AUTOSAR XML (schema 00048)
package /AUTOLIV/SoftwareComponents/BFS
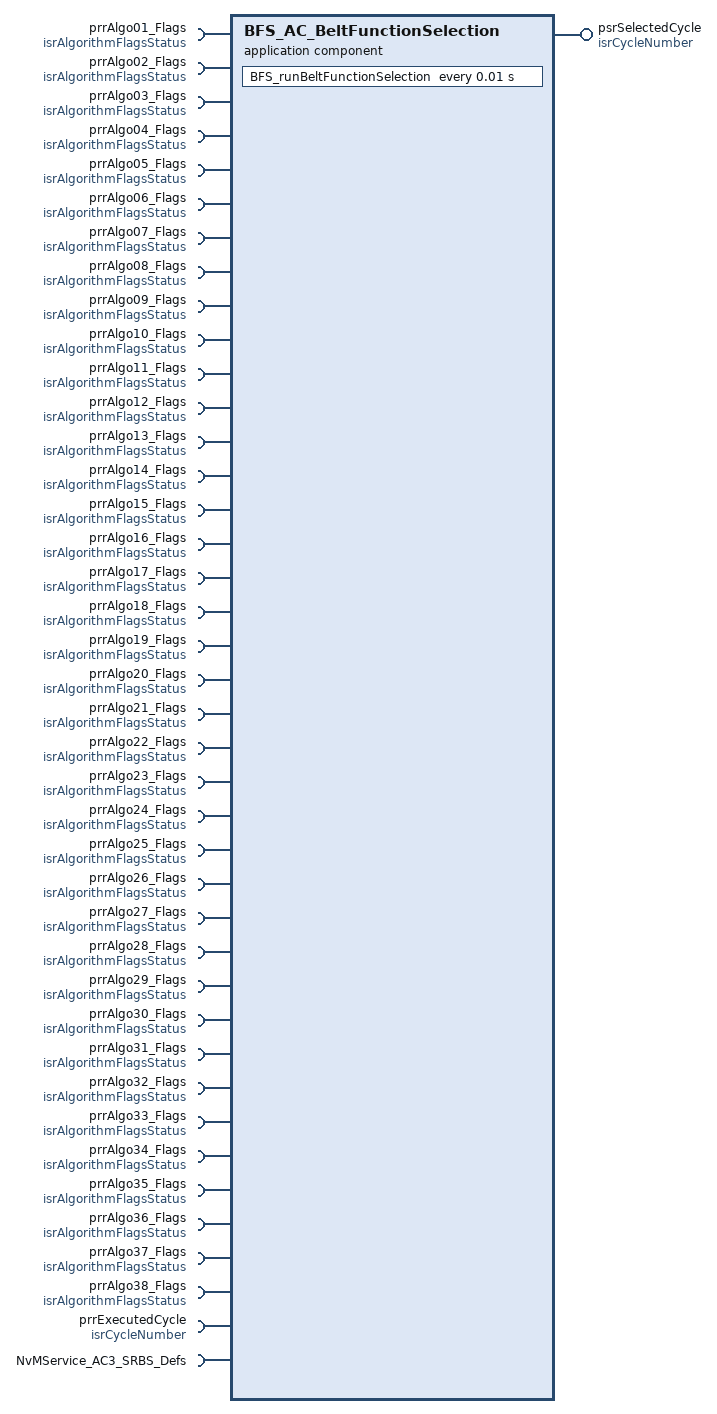
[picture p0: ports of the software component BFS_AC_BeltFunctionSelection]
  application sw component type BFS_AC_BeltFunctionSelection
    39 x require port:
      prrAlgo01_Flags: required-interface=isrAlgorithmFlagsStatus
        required-com-specs:
          data-element=b8InterruptFlag, init-value=constant-reference=APPLINIT_KB8_ALGO_FLAG_FALSE
          data-element=b8PreActivationFlag, init-value=constant-reference=APPLINIT_KB8_ALGO_FLAG_FALSE
          data-element=b8PreConditionsFlag, init-value=constant-reference=APPLINIT_KB8_ALGO_FLAG_FALSE
          data-element=b8TriggerFlag, init-value=constant-reference=APPLINIT_KB8_ALGO_FLAG_FALSE
          data-element=u8TriggeringSource, init-value=constant-reference=APPLINIT_KU8_TRIGGERING_SOURCE_NO
      prrAlgo02_Flags: required-interface=isrAlgorithmFlagsStatus
        required-com-specs:
          data-element=b8InterruptFlag, init-value=constant-reference=APPLINIT_KB8_ALGO_FLAG_FALSE
          data-element=b8PreActivationFlag, init-value=constant-reference=APPLINIT_KB8_ALGO_FLAG_FALSE
          data-element=b8PreConditionsFlag, init-value=constant-reference=APPLINIT_KB8_ALGO_FLAG_FALSE
          data-element=b8TriggerFlag, init-value=constant-reference=APPLINIT_KB8_ALGO_FLAG_FALSE
          data-element=u8TriggeringSource, init-value=constant-reference=APPLINIT_KU8_TRIGGERING_SOURCE_NO
      prrAlgo03_Flags: required-interface=isrAlgorithmFlagsStatus
        required-com-specs:
          data-element=b8InterruptFlag, init-value=constant-reference=APPLINIT_KB8_ALGO_FLAG_FALSE
          data-element=b8PreActivationFlag, init-value=constant-reference=APPLINIT_KB8_ALGO_FLAG_FALSE
          data-element=b8PreConditionsFlag, init-value=constant-reference=APPLINIT_KB8_ALGO_FLAG_FALSE
          data-element=b8TriggerFlag, init-value=constant-reference=APPLINIT_KB8_ALGO_FLAG_FALSE
          data-element=u8TriggeringSource, init-value=constant-reference=APPLINIT_KU8_TRIGGERING_SOURCE_NO
      prrAlgo04_Flags: required-interface=isrAlgorithmFlagsStatus
        required-com-specs:
          data-element=b8InterruptFlag, init-value=constant-reference=APPLINIT_KB8_ALGO_FLAG_FALSE
          data-element=b8PreActivationFlag, init-value=constant-reference=APPLINIT_KB8_ALGO_FLAG_FALSE
          data-element=b8PreConditionsFlag, init-value=constant-reference=APPLINIT_KB8_ALGO_FLAG_FALSE
          data-element=b8TriggerFlag, init-value=constant-reference=APPLINIT_KB8_ALGO_FLAG_FALSE
          data-element=u8TriggeringSource, init-value=constant-reference=APPLINIT_KU8_TRIGGERING_SOURCE_NO
      prrAlgo05_Flags: required-interface=isrAlgorithmFlagsStatus
        required-com-specs:
          data-element=b8InterruptFlag, init-value=constant-reference=APPLINIT_KB8_ALGO_FLAG_FALSE
          data-element=b8PreActivationFlag, init-value=constant-reference=APPLINIT_KB8_ALGO_FLAG_FALSE
          data-element=b8PreConditionsFlag, init-value=constant-reference=APPLINIT_KB8_ALGO_FLAG_FALSE
          data-element=b8TriggerFlag, init-value=constant-reference=APPLINIT_KB8_ALGO_FLAG_FALSE
          data-element=u8TriggeringSource, init-value=constant-reference=APPLINIT_KU8_TRIGGERING_SOURCE_NO
      prrAlgo06_Flags: required-interface=isrAlgorithmFlagsStatus
        required-com-specs:
          data-element=b8InterruptFlag, init-value=constant-reference=APPLINIT_KB8_ALGO_FLAG_FALSE
          data-element=b8PreActivationFlag, init-value=constant-reference=APPLINIT_KB8_ALGO_FLAG_FALSE
          data-element=b8PreConditionsFlag, init-value=constant-reference=APPLINIT_KB8_ALGO_FLAG_FALSE
          data-element=b8TriggerFlag, init-value=constant-reference=APPLINIT_KB8_ALGO_FLAG_FALSE
          data-element=u8TriggeringSource, init-value=constant-reference=APPLINIT_KU8_TRIGGERING_SOURCE_NO
      prrAlgo07_Flags: required-interface=isrAlgorithmFlagsStatus
        required-com-specs:
          data-element=b8InterruptFlag, init-value=constant-reference=APPLINIT_KB8_ALGO_FLAG_FALSE
          data-element=b8PreActivationFlag, init-value=constant-reference=APPLINIT_KB8_ALGO_FLAG_FALSE
          data-element=b8PreConditionsFlag, init-value=constant-reference=APPLINIT_KB8_ALGO_FLAG_FALSE
          data-element=b8TriggerFlag, init-value=constant-reference=APPLINIT_KB8_ALGO_FLAG_FALSE
          data-element=u8TriggeringSource, init-value=constant-reference=APPLINIT_KU8_TRIGGERING_SOURCE_NO
      prrAlgo08_Flags: required-interface=isrAlgorithmFlagsStatus
        required-com-specs:
          data-element=b8InterruptFlag, init-value=constant-reference=APPLINIT_KB8_ALGO_FLAG_FALSE
          data-element=b8PreActivationFlag, init-value=constant-reference=APPLINIT_KB8_ALGO_FLAG_FALSE
          data-element=b8PreConditionsFlag, init-value=constant-reference=APPLINIT_KB8_ALGO_FLAG_FALSE
          data-element=b8TriggerFlag, init-value=constant-reference=APPLINIT_KB8_ALGO_FLAG_FALSE
          data-element=u8TriggeringSource, init-value=constant-reference=APPLINIT_KU8_TRIGGERING_SOURCE_NO
      prrAlgo09_Flags: required-interface=isrAlgorithmFlagsStatus
        required-com-specs:
          data-element=b8InterruptFlag, init-value=constant-reference=APPLINIT_KB8_ALGO_FLAG_FALSE
          data-element=b8PreActivationFlag, init-value=constant-reference=APPLINIT_KB8_ALGO_FLAG_FALSE
          data-element=b8PreConditionsFlag, init-value=constant-reference=APPLINIT_KB8_ALGO_FLAG_FALSE
          data-element=b8TriggerFlag, init-value=constant-reference=APPLINIT_KB8_ALGO_FLAG_FALSE
          data-element=u8TriggeringSource, init-value=constant-reference=APPLINIT_KU8_TRIGGERING_SOURCE_NO
      prrAlgo10_Flags: required-interface=isrAlgorithmFlagsStatus
        required-com-specs:
          data-element=b8InterruptFlag, init-value=constant-reference=APPLINIT_KB8_ALGO_FLAG_FALSE
          data-element=b8PreActivationFlag, init-value=constant-reference=APPLINIT_KB8_ALGO_FLAG_FALSE
          data-element=b8PreConditionsFlag, init-value=constant-reference=APPLINIT_KB8_ALGO_FLAG_FALSE
          data-element=b8TriggerFlag, init-value=constant-reference=APPLINIT_KB8_ALGO_FLAG_FALSE
          data-element=u8TriggeringSource, init-value=constant-reference=APPLINIT_KU8_TRIGGERING_SOURCE_NO
      prrAlgo11_Flags: required-interface=isrAlgorithmFlagsStatus
        required-com-specs:
          data-element=b8InterruptFlag, init-value=constant-reference=APPLINIT_KB8_ALGO_FLAG_FALSE
          data-element=b8PreActivationFlag, init-value=constant-reference=APPLINIT_KB8_ALGO_FLAG_FALSE
          data-element=b8PreConditionsFlag, init-value=constant-reference=APPLINIT_KB8_ALGO_FLAG_FALSE
          data-element=b8TriggerFlag, init-value=constant-reference=APPLINIT_KB8_ALGO_FLAG_FALSE
          data-element=u8TriggeringSource, init-value=constant-reference=APPLINIT_KU8_TRIGGERING_SOURCE_NO
      prrAlgo12_Flags: required-interface=isrAlgorithmFlagsStatus
        required-com-specs:
          data-element=b8InterruptFlag, init-value=constant-reference=APPLINIT_KB8_ALGO_FLAG_FALSE
          data-element=b8PreActivationFlag, init-value=constant-reference=APPLINIT_KB8_ALGO_FLAG_FALSE
          data-element=b8PreConditionsFlag, init-value=constant-reference=APPLINIT_KB8_ALGO_FLAG_FALSE
          data-element=b8TriggerFlag, init-value=constant-reference=APPLINIT_KB8_ALGO_FLAG_FALSE
          data-element=u8TriggeringSource, init-value=constant-reference=APPLINIT_KU8_TRIGGERING_SOURCE_NO
      prrAlgo13_Flags: required-interface=isrAlgorithmFlagsStatus
        required-com-specs:
          data-element=b8InterruptFlag, init-value=constant-reference=APPLINIT_KB8_ALGO_FLAG_FALSE
          data-element=b8PreActivationFlag, init-value=constant-reference=APPLINIT_KB8_ALGO_FLAG_FALSE
          data-element=b8PreConditionsFlag, init-value=constant-reference=APPLINIT_KB8_ALGO_FLAG_FALSE
          data-element=b8TriggerFlag, init-value=constant-reference=APPLINIT_KB8_ALGO_FLAG_FALSE
          data-element=u8TriggeringSource, init-value=constant-reference=APPLINIT_KU8_TRIGGERING_SOURCE_NO
      prrAlgo14_Flags: required-interface=isrAlgorithmFlagsStatus
        required-com-specs:
          data-element=b8InterruptFlag, init-value=constant-reference=APPLINIT_KB8_ALGO_FLAG_FALSE
          data-element=b8PreActivationFlag, init-value=constant-reference=APPLINIT_KB8_ALGO_FLAG_FALSE
          data-element=b8PreConditionsFlag, init-value=constant-reference=APPLINIT_KB8_ALGO_FLAG_FALSE
          data-element=b8TriggerFlag, init-value=constant-reference=APPLINIT_KB8_ALGO_FLAG_FALSE
          data-element=u8TriggeringSource, init-value=constant-reference=APPLINIT_KU8_TRIGGERING_SOURCE_NO
      prrAlgo15_Flags: required-interface=isrAlgorithmFlagsStatus
        required-com-specs:
          data-element=b8InterruptFlag, init-value=constant-reference=APPLINIT_KB8_ALGO_FLAG_FALSE
          data-element=b8PreActivationFlag, init-value=constant-reference=APPLINIT_KB8_ALGO_FLAG_FALSE
          data-element=b8PreConditionsFlag, init-value=constant-reference=APPLINIT_KB8_ALGO_FLAG_FALSE
          data-element=b8TriggerFlag, init-value=constant-reference=APPLINIT_KB8_ALGO_FLAG_FALSE
          data-element=u8TriggeringSource, init-value=constant-reference=APPLINIT_KU8_TRIGGERING_SOURCE_NO
      prrAlgo16_Flags: required-interface=isrAlgorithmFlagsStatus
        required-com-specs:
          data-element=b8InterruptFlag, init-value=constant-reference=APPLINIT_KB8_ALGO_FLAG_FALSE
          data-element=b8PreActivationFlag, init-value=constant-reference=APPLINIT_KB8_ALGO_FLAG_FALSE
          data-element=b8PreConditionsFlag, init-value=constant-reference=APPLINIT_KB8_ALGO_FLAG_FALSE
          data-element=b8TriggerFlag, init-value=constant-reference=APPLINIT_KB8_ALGO_FLAG_FALSE
          data-element=u8TriggeringSource, init-value=constant-reference=APPLINIT_KU8_TRIGGERING_SOURCE_NO
      prrAlgo17_Flags: required-interface=isrAlgorithmFlagsStatus
        required-com-specs:
          data-element=b8InterruptFlag, init-value=constant-reference=APPLINIT_KB8_ALGO_FLAG_FALSE
          data-element=b8PreActivationFlag, init-value=constant-reference=APPLINIT_KB8_ALGO_FLAG_FALSE
          data-element=b8PreConditionsFlag, init-value=constant-reference=APPLINIT_KB8_ALGO_FLAG_FALSE
          data-element=b8TriggerFlag, init-value=constant-reference=APPLINIT_KB8_ALGO_FLAG_FALSE
          data-element=u8TriggeringSource, init-value=constant-reference=APPLINIT_KU8_TRIGGERING_SOURCE_NO
      prrAlgo18_Flags: required-interface=isrAlgorithmFlagsStatus
        required-com-specs:
          data-element=b8InterruptFlag, init-value=constant-reference=APPLINIT_KB8_ALGO_FLAG_FALSE
          data-element=b8PreActivationFlag, init-value=constant-reference=APPLINIT_KB8_ALGO_FLAG_FALSE
          data-element=b8PreConditionsFlag, init-value=constant-reference=APPLINIT_KB8_ALGO_FLAG_FALSE
          data-element=b8TriggerFlag, init-value=constant-reference=APPLINIT_KB8_ALGO_FLAG_FALSE
          data-element=u8TriggeringSource, init-value=constant-reference=APPLINIT_KU8_TRIGGERING_SOURCE_NO
      prrAlgo19_Flags: required-interface=isrAlgorithmFlagsStatus
        required-com-specs:
          data-element=b8InterruptFlag, init-value=constant-reference=APPLINIT_KB8_ALGO_FLAG_FALSE
          data-element=b8PreActivationFlag, init-value=constant-reference=APPLINIT_KB8_ALGO_FLAG_FALSE
          data-element=b8PreConditionsFlag, init-value=constant-reference=APPLINIT_KB8_ALGO_FLAG_FALSE
          data-element=b8TriggerFlag, init-value=constant-reference=APPLINIT_KB8_ALGO_FLAG_FALSE
          data-element=u8TriggeringSource, init-value=constant-reference=APPLINIT_KU8_TRIGGERING_SOURCE_NO
      prrAlgo20_Flags: required-interface=isrAlgorithmFlagsStatus
        required-com-specs:
          data-element=b8InterruptFlag, init-value=constant-reference=APPLINIT_KB8_ALGO_FLAG_FALSE
          data-element=b8PreActivationFlag, init-value=constant-reference=APPLINIT_KB8_ALGO_FLAG_FALSE
          data-element=b8PreConditionsFlag, init-value=constant-reference=APPLINIT_KB8_ALGO_FLAG_FALSE
          data-element=b8TriggerFlag, init-value=constant-reference=APPLINIT_KB8_ALGO_FLAG_FALSE
          data-element=u8TriggeringSource, init-value=constant-reference=APPLINIT_KU8_TRIGGERING_SOURCE_NO
      prrAlgo21_Flags: required-interface=isrAlgorithmFlagsStatus
        required-com-specs:
          data-element=b8InterruptFlag, init-value=constant-reference=APPLINIT_KB8_ALGO_FLAG_FALSE
          data-element=b8PreActivationFlag, init-value=constant-reference=APPLINIT_KB8_ALGO_FLAG_FALSE
          data-element=b8PreConditionsFlag, init-value=constant-reference=APPLINIT_KB8_ALGO_FLAG_FALSE
          data-element=b8TriggerFlag, init-value=constant-reference=APPLINIT_KB8_ALGO_FLAG_FALSE
          data-element=u8TriggeringSource, init-value=constant-reference=APPLINIT_KU8_TRIGGERING_SOURCE_NO
      prrAlgo22_Flags: required-interface=isrAlgorithmFlagsStatus
        required-com-specs:
          data-element=b8InterruptFlag, init-value=constant-reference=APPLINIT_KB8_ALGO_FLAG_FALSE
          data-element=b8PreActivationFlag, init-value=constant-reference=APPLINIT_KB8_ALGO_FLAG_FALSE
          data-element=b8PreConditionsFlag, init-value=constant-reference=APPLINIT_KB8_ALGO_FLAG_FALSE
          data-element=b8TriggerFlag, init-value=constant-reference=APPLINIT_KB8_ALGO_FLAG_FALSE
          data-element=u8TriggeringSource, init-value=constant-reference=APPLINIT_KU8_TRIGGERING_SOURCE_NO
      prrAlgo23_Flags: required-interface=isrAlgorithmFlagsStatus
        required-com-specs:
          data-element=b8InterruptFlag, init-value=constant-reference=APPLINIT_KB8_ALGO_FLAG_FALSE
          data-element=b8PreActivationFlag, init-value=constant-reference=APPLINIT_KB8_ALGO_FLAG_FALSE
          data-element=b8PreConditionsFlag, init-value=constant-reference=APPLINIT_KB8_ALGO_FLAG_FALSE
          data-element=b8TriggerFlag, init-value=constant-reference=APPLINIT_KB8_ALGO_FLAG_FALSE
          data-element=u8TriggeringSource, init-value=constant-reference=APPLINIT_KU8_TRIGGERING_SOURCE_NO
      prrAlgo24_Flags: required-interface=isrAlgorithmFlagsStatus
        required-com-specs:
          data-element=b8InterruptFlag, init-value=constant-reference=APPLINIT_KB8_ALGO_FLAG_FALSE
          data-element=b8PreActivationFlag, init-value=constant-reference=APPLINIT_KB8_ALGO_FLAG_FALSE
          data-element=b8PreConditionsFlag, init-value=constant-reference=APPLINIT_KB8_ALGO_FLAG_FALSE
          data-element=b8TriggerFlag, init-value=constant-reference=APPLINIT_KB8_ALGO_FLAG_FALSE
          data-element=u8TriggeringSource, init-value=constant-reference=APPLINIT_KU8_TRIGGERING_SOURCE_NO
      prrAlgo25_Flags: required-interface=isrAlgorithmFlagsStatus
        required-com-specs:
          data-element=b8InterruptFlag, init-value=constant-reference=APPLINIT_KB8_ALGO_FLAG_FALSE
          data-element=b8PreActivationFlag, init-value=constant-reference=APPLINIT_KB8_ALGO_FLAG_FALSE
          data-element=b8PreConditionsFlag, init-value=constant-reference=APPLINIT_KB8_ALGO_FLAG_FALSE
          data-element=b8TriggerFlag, init-value=constant-reference=APPLINIT_KB8_ALGO_FLAG_FALSE
          data-element=u8TriggeringSource, init-value=constant-reference=APPLINIT_KU8_TRIGGERING_SOURCE_NO
      prrAlgo26_Flags: required-interface=isrAlgorithmFlagsStatus
        required-com-specs:
          data-element=b8InterruptFlag, init-value=constant-reference=APPLINIT_KB8_ALGO_FLAG_FALSE
          data-element=b8PreActivationFlag, init-value=constant-reference=APPLINIT_KB8_ALGO_FLAG_FALSE
          data-element=b8PreConditionsFlag, init-value=constant-reference=APPLINIT_KB8_ALGO_FLAG_FALSE
          data-element=b8TriggerFlag, init-value=constant-reference=APPLINIT_KB8_ALGO_FLAG_FALSE
          data-element=u8TriggeringSource, init-value=constant-reference=APPLINIT_KU8_TRIGGERING_SOURCE_NO
      prrAlgo27_Flags: required-interface=isrAlgorithmFlagsStatus
        required-com-specs:
          data-element=b8InterruptFlag, init-value=constant-reference=APPLINIT_KB8_ALGO_FLAG_FALSE
          data-element=b8PreActivationFlag, init-value=constant-reference=APPLINIT_KB8_ALGO_FLAG_FALSE
          data-element=b8PreConditionsFlag, init-value=constant-reference=APPLINIT_KB8_ALGO_FLAG_FALSE
          data-element=b8TriggerFlag, init-value=constant-reference=APPLINIT_KB8_ALGO_FLAG_FALSE
          data-element=u8TriggeringSource, init-value=constant-reference=APPLINIT_KU8_TRIGGERING_SOURCE_NO
      prrAlgo28_Flags: required-interface=isrAlgorithmFlagsStatus
        required-com-specs:
          data-element=b8InterruptFlag, init-value=constant-reference=APPLINIT_KB8_ALGO_FLAG_FALSE
          data-element=b8PreActivationFlag, init-value=constant-reference=APPLINIT_KB8_ALGO_FLAG_FALSE
          data-element=b8PreConditionsFlag, init-value=constant-reference=APPLINIT_KB8_ALGO_FLAG_FALSE
          data-element=b8TriggerFlag, init-value=constant-reference=APPLINIT_KB8_ALGO_FLAG_FALSE
          data-element=u8TriggeringSource, init-value=constant-reference=APPLINIT_KU8_TRIGGERING_SOURCE_NO
      prrAlgo29_Flags: required-interface=isrAlgorithmFlagsStatus
        required-com-specs:
          data-element=b8InterruptFlag, init-value=constant-reference=APPLINIT_KB8_ALGO_FLAG_FALSE
          data-element=b8PreActivationFlag, init-value=constant-reference=APPLINIT_KB8_ALGO_FLAG_FALSE
          data-element=b8PreConditionsFlag, init-value=constant-reference=APPLINIT_KB8_ALGO_FLAG_FALSE
          data-element=b8TriggerFlag, init-value=constant-reference=APPLINIT_KB8_ALGO_FLAG_FALSE
          data-element=u8TriggeringSource, init-value=constant-reference=APPLINIT_KU8_TRIGGERING_SOURCE_NO
      prrAlgo30_Flags: required-interface=isrAlgorithmFlagsStatus
        required-com-specs:
          data-element=b8InterruptFlag, init-value=constant-reference=APPLINIT_KB8_ALGO_FLAG_FALSE
          data-element=b8PreActivationFlag, init-value=constant-reference=APPLINIT_KB8_ALGO_FLAG_FALSE
          data-element=b8PreConditionsFlag, init-value=constant-reference=APPLINIT_KB8_ALGO_FLAG_FALSE
          data-element=b8TriggerFlag, init-value=constant-reference=APPLINIT_KB8_ALGO_FLAG_FALSE
          data-element=u8TriggeringSource, init-value=constant-reference=APPLINIT_KU8_TRIGGERING_SOURCE_NO
      prrAlgo31_Flags: required-interface=isrAlgorithmFlagsStatus
        required-com-specs:
          data-element=b8InterruptFlag, init-value=constant-reference=APPLINIT_KB8_ALGO_FLAG_FALSE
          data-element=b8PreActivationFlag, init-value=constant-reference=APPLINIT_KB8_ALGO_FLAG_FALSE
          data-element=b8PreConditionsFlag, init-value=constant-reference=APPLINIT_KB8_ALGO_FLAG_FALSE
          data-element=b8TriggerFlag, init-value=constant-reference=APPLINIT_KB8_ALGO_FLAG_FALSE
          data-element=u8TriggeringSource, init-value=constant-reference=APPLINIT_KU8_TRIGGERING_SOURCE_NO
      prrAlgo32_Flags: required-interface=isrAlgorithmFlagsStatus
        required-com-specs:
          data-element=b8InterruptFlag, init-value=constant-reference=APPLINIT_KB8_ALGO_FLAG_FALSE
          data-element=b8PreActivationFlag, init-value=constant-reference=APPLINIT_KB8_ALGO_FLAG_FALSE
          data-element=b8PreConditionsFlag, init-value=constant-reference=APPLINIT_KB8_ALGO_FLAG_FALSE
          data-element=b8TriggerFlag, init-value=constant-reference=APPLINIT_KB8_ALGO_FLAG_FALSE
          data-element=u8TriggeringSource, init-value=constant-reference=APPLINIT_KU8_TRIGGERING_SOURCE_NO
      prrAlgo33_Flags: required-interface=isrAlgorithmFlagsStatus
        required-com-specs:
          data-element=b8InterruptFlag, init-value=constant-reference=APPLINIT_KB8_ALGO_FLAG_FALSE
          data-element=b8PreActivationFlag, init-value=constant-reference=APPLINIT_KB8_ALGO_FLAG_FALSE
          data-element=b8PreConditionsFlag, init-value=constant-reference=APPLINIT_KB8_ALGO_FLAG_FALSE
          data-element=b8TriggerFlag, init-value=constant-reference=APPLINIT_KB8_ALGO_FLAG_FALSE
          data-element=u8TriggeringSource, init-value=constant-reference=APPLINIT_KU8_TRIGGERING_SOURCE_NO
      prrAlgo34_Flags: required-interface=isrAlgorithmFlagsStatus
        required-com-specs:
          data-element=b8InterruptFlag, init-value=constant-reference=APPLINIT_KB8_ALGO_FLAG_FALSE
          data-element=b8PreActivationFlag, init-value=constant-reference=APPLINIT_KB8_ALGO_FLAG_FALSE
          data-element=b8PreConditionsFlag, init-value=constant-reference=APPLINIT_KB8_ALGO_FLAG_FALSE
          data-element=b8TriggerFlag, init-value=constant-reference=APPLINIT_KB8_ALGO_FLAG_FALSE
          data-element=u8TriggeringSource, init-value=constant-reference=APPLINIT_KU8_TRIGGERING_SOURCE_NO
      prrAlgo35_Flags: required-interface=isrAlgorithmFlagsStatus
        required-com-specs:
          data-element=b8InterruptFlag, init-value=constant-reference=APPLINIT_KB8_ALGO_FLAG_FALSE
          data-element=b8PreActivationFlag, init-value=constant-reference=APPLINIT_KB8_ALGO_FLAG_FALSE
          data-element=b8PreConditionsFlag, init-value=constant-reference=APPLINIT_KB8_ALGO_FLAG_FALSE
          data-element=b8TriggerFlag, init-value=constant-reference=APPLINIT_KB8_ALGO_FLAG_FALSE
          data-element=u8TriggeringSource, init-value=constant-reference=APPLINIT_KU8_TRIGGERING_SOURCE_NO
      prrAlgo36_Flags: required-interface=isrAlgorithmFlagsStatus
        required-com-specs:
          data-element=b8InterruptFlag, init-value=constant-reference=APPLINIT_KB8_ALGO_FLAG_FALSE
          data-element=b8PreActivationFlag, init-value=constant-reference=APPLINIT_KB8_ALGO_FLAG_FALSE
          data-element=b8PreConditionsFlag, init-value=constant-reference=APPLINIT_KB8_ALGO_FLAG_FALSE
          data-element=b8TriggerFlag, init-value=constant-reference=APPLINIT_KB8_ALGO_FLAG_FALSE
          data-element=u8TriggeringSource, init-value=constant-reference=APPLINIT_KU8_TRIGGERING_SOURCE_NO
      prrAlgo37_Flags: required-interface=isrAlgorithmFlagsStatus
        required-com-specs:
          data-element=b8InterruptFlag, init-value=constant-reference=APPLINIT_KB8_ALGO_FLAG_FALSE
          data-element=b8PreActivationFlag, init-value=constant-reference=APPLINIT_KB8_ALGO_FLAG_FALSE
          data-element=b8PreConditionsFlag, init-value=constant-reference=APPLINIT_KB8_ALGO_FLAG_FALSE
          data-element=b8TriggerFlag, init-value=constant-reference=APPLINIT_KB8_ALGO_FLAG_FALSE
          data-element=u8TriggeringSource, init-value=constant-reference=APPLINIT_KU8_TRIGGERING_SOURCE_NO
      prrAlgo38_Flags: required-interface=isrAlgorithmFlagsStatus
        required-com-specs:
          data-element=b8InterruptFlag, init-value=constant-reference=APPLINIT_KB8_ALGO_FLAG_FALSE
          data-element=b8PreActivationFlag, init-value=constant-reference=APPLINIT_KB8_ALGO_FLAG_FALSE
          data-element=b8PreConditionsFlag, init-value=constant-reference=APPLINIT_KB8_ALGO_FLAG_FALSE
          data-element=b8TriggerFlag, init-value=constant-reference=APPLINIT_KB8_ALGO_FLAG_FALSE
          data-element=u8TriggeringSource, init-value=constant-reference=APPLINIT_KU8_TRIGGERING_SOURCE_NO
      prrExecutedCycle: nonqueued-receiver-com-spec{data-element=u8CycleNumber, init-value=constant-reference=APPLINIT_KU8_CYCLE_NUMBER_NONE}, required-interface=isrCycleNumber
    provide port psrSelectedCycle: nonqueued-sender-com-spec{data-element=u8CycleNumber, init-value=constant-reference=APPLINIT_KU8_CYCLE_NUMBER_NONE}, provided-interface=isrCycleNumber
    require port NvMService_AC3_SRBS_Defs: required-com-specs=[WriteBlock, SetRamBlockStatus, RestoreBlockDefaults, ReadBlock, InvalidateNvBlock, GetErrorStatus, EraseBlock], required-interface=NvMService_AC3_SRBS_Defs
    behavior BFS_IB_BeltFunctionSelection: data-type-mapping=DataTypeMappingSet_PP4G
      timing event BFS_evBeltFunctionSelection: start-on-event=BFS_runBeltFunctionSelection, period=0.01
      runnable BFS_runBeltFunctionSelection
        data-read-access:
          access DRA_prrExecut_u8CycleNumber: accessed-variable=prrExecutedCycle.u8CycleNumber  # ARCH_SW_BFS_0090
        data-receive-point-by-arguments:
          116 x access:
            DRP_prrAlgo01_InterruptFlag: accessed-variable=prrAlgo01_Flags.b8InterruptFlag  # ARCH_SW_BFS_0031
            DRP_prrAlgo01_b8TriggerFlag: accessed-variable=prrAlgo01_Flags.b8TriggerFlag  # ARCH_SW_BFS_0021
            DRP_prrAlgo02_InterruptFlag: accessed-variable=prrAlgo02_Flags.b8InterruptFlag  # ARCH_SW_BFS_0032
            DRP_prrAlgo02_b8TriggerFlag: accessed-variable=prrAlgo02_Flags.b8TriggerFlag  # ARCH_SW_BFS_0022
            DRP_prrAlgo03_InterruptFlag: accessed-variable=prrAlgo03_Flags.b8InterruptFlag  # ARCH_SW_BFS_0033
            DRP_prrAlgo03_b8TriggerFlag: accessed-variable=prrAlgo03_Flags.b8TriggerFlag  # ARCH_SW_BFS_0023
            DRP_prrAlgo04_InterruptFlag: accessed-variable=prrAlgo04_Flags.b8InterruptFlag  # ARCH_SW_BFS_0034
            DRP_prrAlgo04_b8TriggerFlag: accessed-variable=prrAlgo04_Flags.b8TriggerFlag  # ARCH_SW_BFS_0024
            DRP_prrAlgo05_InterruptFlag: accessed-variable=prrAlgo05_Flags.b8InterruptFlag  # ARCH_SW_BFS_0035
            DRP_prrAlgo05_b8TriggerFlag: accessed-variable=prrAlgo05_Flags.b8TriggerFlag  # ARCH_SW_BFS_0025
            DRP_prrAlgo06_InterruptFlag: accessed-variable=prrAlgo06_Flags.b8InterruptFlag  # ARCH_SW_BFS_0036
            DRP_prrAlgo06_b8TriggerFlag: accessed-variable=prrAlgo06_Flags.b8TriggerFlag  # ARCH_SW_BFS_0026
            DRP_prrAlgo07_InterruptFlag: accessed-variable=prrAlgo07_Flags.b8InterruptFlag  # ARCH_SW_BFS_0037
            DRP_prrAlgo07_b8TriggerFlag: accessed-variable=prrAlgo07_Flags.b8TriggerFlag  # ARCH_SW_BFS_0027
            DRP_prrAlgo08_InterruptFlag: accessed-variable=prrAlgo08_Flags.b8InterruptFlag  # ARCH_SW_BFS_0038
            DRP_prrAlgo08_b8TriggerFlag: accessed-variable=prrAlgo08_Flags.b8TriggerFlag  # ARCH_SW_BFS_0028
            DRP_prrAlgo09_InterruptFlag: accessed-variable=prrAlgo09_Flags.b8InterruptFlag  # ARCH_SW_BFS_0042
            DRP_prrAlgo09_b8TriggerFlag: accessed-variable=prrAlgo09_Flags.b8TriggerFlag  # ARCH_SW_BFS_0041
            DRP_prrAlgo10_InterruptFlag: accessed-variable=prrAlgo10_Flags.b8InterruptFlag
            DRP_prrAlgo10_b8TriggerFlag: accessed-variable=prrAlgo10_Flags.b8TriggerFlag
            DRP_prrAlgo11_InterruptFlag: accessed-variable=prrAlgo11_Flags.b8InterruptFlag  # ARCH_SW_BFS_0054
            DRP_prrAlgo11_b8TriggerFlag: accessed-variable=prrAlgo11_Flags.b8TriggerFlag  # ARCH_SW_BFS_0051
            DRP_prrAlgo12_InterruptFlag: accessed-variable=prrAlgo12_Flags.b8InterruptFlag  # ARCH_SW_BFS_0055
            DRP_prrAlgo12_b8TriggerFlag: accessed-variable=prrAlgo12_Flags.b8TriggerFlag  # ARCH_SW_BFS_0052
            DRP_prrAlgo13_InterruptFlag: accessed-variable=prrAlgo13_Flags.b8InterruptFlag  # ARCH_SW_BFS_0056
            DRP_prrAlgo13_b8TriggerFlag: accessed-variable=prrAlgo13_Flags.b8TriggerFlag  # ARCH_SW_BFS_0053
            DRP_prrAlgo14_InterruptFlag: accessed-variable=prrAlgo14_Flags.b8InterruptFlag  # ARCH_SW_BFS_0064
            DRP_prrAlgo14_b8TriggerFlag: accessed-variable=prrAlgo14_Flags.b8TriggerFlag  # ARCH_SW_BFS_0061
            DRP_prrAlgo15_InterruptFlag: accessed-variable=prrAlgo15_Flags.b8InterruptFlag  # ARCH_SW_BFS_0065
            DRP_prrAlgo15_b8TriggerFlag: accessed-variable=prrAlgo15_Flags.b8TriggerFlag  # ARCH_SW_BFS_0062
            DRP_prrAlgo16_InterruptFlag: accessed-variable=prrAlgo16_Flags.b8InterruptFlag  # ARCH_SW_BFS_0075
            DRP_prrAlgo16_b8TriggerFlag: accessed-variable=prrAlgo16_Flags.b8TriggerFlag  # ARCH_SW_BFS_0071
            DRP_prrAlgo17_InterruptFlag: accessed-variable=prrAlgo17_Flags.b8InterruptFlag  # ARCH_SW_BFS_0076
            DRP_prrAlgo17_b8TriggerFlag: accessed-variable=prrAlgo17_Flags.b8TriggerFlag  # ARCH_SW_BFS_0072
            DRP_prrAlgo18_InterruptFlag: accessed-variable=prrAlgo18_Flags.b8InterruptFlag  # ARCH_SW_BFS_0077
            DRP_prrAlgo18_b8TriggerFlag: accessed-variable=prrAlgo18_Flags.b8TriggerFlag  # ARCH_SW_BFS_0073
            DRP_prrAlgo19_InterruptFlag: accessed-variable=prrAlgo19_Flags.b8InterruptFlag  # ARCH_SW_BFS_0078
            DRP_prrAlgo19_b8TriggerFlag: accessed-variable=prrAlgo19_Flags.b8TriggerFlag  # ARCH_SW_BFS_0074
            DRP_prrAlgo20_InterruptFlag: accessed-variable=prrAlgo20_Flags.b8InterruptFlag  # ARCH_SW_BFS_0084
            DRP_prrAlgo20_b8TriggerFlag: accessed-variable=prrAlgo20_Flags.b8TriggerFlag  # ARCH_SW_BFS_0081
            DRP_prrAlgo21_InterruptFlag: accessed-variable=prrAlgo21_Flags.b8InterruptFlag  # ARCH_SW_BFS_0085
            DRP_prrAlgo21_b8TriggerFlag: accessed-variable=prrAlgo21_Flags.b8TriggerFlag  # ARCH_SW_BFS_0082
            DRP_prrAlgo22_InterruptFlag: accessed-variable=prrAlgo22_Flags.b8InterruptFlag
            DRP_prrAlgo22_b8TriggerFlag: accessed-variable=prrAlgo22_Flags.b8TriggerFlag
            DRP_prrAlgo23_InterruptFlag: accessed-variable=prrAlgo23_Flags.b8InterruptFlag
            DRP_prrAlgo23_b8TriggerFlag: accessed-variable=prrAlgo23_Flags.b8TriggerFlag
            DRP_prrAlgo24_InterruptFlag: accessed-variable=prrAlgo24_Flags.b8InterruptFlag
            DRP_prrAlgo24_b8TriggerFlag: accessed-variable=prrAlgo24_Flags.b8TriggerFlag
            DRP_prrAlgo25_InterruptFlag: accessed-variable=prrAlgo25_Flags.b8InterruptFlag
            DRP_prrAlgo25_b8TriggerFlag: accessed-variable=prrAlgo25_Flags.b8TriggerFlag
            DRP_prrAlgo26_InterruptFlag: accessed-variable=prrAlgo26_Flags.b8InterruptFlag
            DRP_prrAlgo26_b8TriggerFlag: accessed-variable=prrAlgo26_Flags.b8TriggerFlag
            DRP_prrAlgo27_InterruptFlag: accessed-variable=prrAlgo27_Flags.b8InterruptFlag
            DRP_prrAlgo27_b8TriggerFlag: accessed-variable=prrAlgo27_Flags.b8TriggerFlag
            DRP_prrAlgo28_InterruptFlag: accessed-variable=prrAlgo28_Flags.b8InterruptFlag
            DRP_prrAlgo28_b8TriggerFlag: accessed-variable=prrAlgo28_Flags.b8TriggerFlag
            DRP_prrAlgo29_InterruptFlag: accessed-variable=prrAlgo29_Flags.b8InterruptFlag
            DRP_prrAlgo29_b8TriggerFlag: accessed-variable=prrAlgo29_Flags.b8TriggerFlag
            DRP_prrAlgo30_InterruptFlag: accessed-variable=prrAlgo30_Flags.b8InterruptFlag
            DRP_prrAlgo30_b8TriggerFlag: accessed-variable=prrAlgo30_Flags.b8TriggerFlag
            DRP_prrAlgo31_InterruptFlag: accessed-variable=prrAlgo31_Flags.b8InterruptFlag
            DRP_prrAlgo31_b8TriggerFlag: accessed-variable=prrAlgo31_Flags.b8TriggerFlag
            DRP_prrAlgo32_InterruptFlag: accessed-variable=prrAlgo32_Flags.b8InterruptFlag
            DRP_prrAlgo32_b8TriggerFlag: accessed-variable=prrAlgo32_Flags.b8TriggerFlag
            DRP_prrAlgo33_InterruptFlag: accessed-variable=prrAlgo33_Flags.b8InterruptFlag
            DRP_prrAlgo33_b8TriggerFlag: accessed-variable=prrAlgo33_Flags.b8TriggerFlag
            DRP_prrAlgo34_InterruptFlag: accessed-variable=prrAlgo34_Flags.b8InterruptFlag
            DRP_prrAlgo34_b8TriggerFlag: accessed-variable=prrAlgo34_Flags.b8TriggerFlag
            DRP_prrAlgo35_InterruptFlag: accessed-variable=prrAlgo35_Flags.b8InterruptFlag
            DRP_prrAlgo35_b8TriggerFlag: accessed-variable=prrAlgo35_Flags.b8TriggerFlag
            DRP_prrAlgo36_InterruptFlag: accessed-variable=prrAlgo36_Flags.b8InterruptFlag
            DRP_prrAlgo36_b8TriggerFlag: accessed-variable=prrAlgo36_Flags.b8TriggerFlag
            DRP_prrAlgo37_InterruptFlag: accessed-variable=prrAlgo37_Flags.b8InterruptFlag
            DRP_prrAlgo37_b8TriggerFlag: accessed-variable=prrAlgo37_Flags.b8TriggerFlag
            DRP_prrAlgo38_InterruptFlag: accessed-variable=prrAlgo38_Flags.b8InterruptFlag
            DRP_prrAlgo38_b8TriggerFlag: accessed-variable=prrAlgo38_Flags.b8TriggerFlag
            drparg_u8TriggeringSource: accessed-variable=prrAlgo01_Flags.u8TriggeringSource
            drparg_u8TriggeringSource1: accessed-variable=prrAlgo02_Flags.u8TriggeringSource
            drparg_u8TriggeringSource10: accessed-variable=prrAlgo11_Flags.u8TriggeringSource
            drparg_u8TriggeringSource11: accessed-variable=prrAlgo12_Flags.u8TriggeringSource
            drparg_u8TriggeringSource12: accessed-variable=prrAlgo13_Flags.u8TriggeringSource
            drparg_u8TriggeringSource13: accessed-variable=prrAlgo14_Flags.u8TriggeringSource
            drparg_u8TriggeringSource14: accessed-variable=prrAlgo15_Flags.u8TriggeringSource
            drparg_u8TriggeringSource15: accessed-variable=prrAlgo16_Flags.u8TriggeringSource
            drparg_u8TriggeringSource16: accessed-variable=prrAlgo17_Flags.u8TriggeringSource
            drparg_u8TriggeringSource17: accessed-variable=prrAlgo18_Flags.u8TriggeringSource
            drparg_u8TriggeringSource18: accessed-variable=prrAlgo19_Flags.u8TriggeringSource
            drparg_u8TriggeringSource19: accessed-variable=prrAlgo20_Flags.u8TriggeringSource
            drparg_u8TriggeringSource2: accessed-variable=prrAlgo03_Flags.u8TriggeringSource
            drparg_u8TriggeringSource20: accessed-variable=prrAlgo21_Flags.u8TriggeringSource
            drparg_u8TriggeringSource21: accessed-variable=prrAlgo22_Flags.u8TriggeringSource
            drparg_u8TriggeringSource22: accessed-variable=prrAlgo23_Flags.u8TriggeringSource
            drparg_u8TriggeringSource23: accessed-variable=prrAlgo24_Flags.u8TriggeringSource
            drparg_u8TriggeringSource24: accessed-variable=prrAlgo25_Flags.u8TriggeringSource
            drparg_u8TriggeringSource25: accessed-variable=prrAlgo26_Flags.u8TriggeringSource
            drparg_u8TriggeringSource26: accessed-variable=prrAlgo27_Flags.u8TriggeringSource
            drparg_u8TriggeringSource27: accessed-variable=prrAlgo28_Flags.u8TriggeringSource
            drparg_u8TriggeringSource28: accessed-variable=prrAlgo29_Flags.u8TriggeringSource
            drparg_u8TriggeringSource29: accessed-variable=prrAlgo30_Flags.u8TriggeringSource
            drparg_u8TriggeringSource3: accessed-variable=prrAlgo04_Flags.u8TriggeringSource
            drparg_u8TriggeringSource30: accessed-variable=prrAlgo31_Flags.u8TriggeringSource
            drparg_u8TriggeringSource31: accessed-variable=prrAlgo32_Flags.u8TriggeringSource
            drparg_u8TriggeringSource32: accessed-variable=prrAlgo33_Flags.u8TriggeringSource
            drparg_u8TriggeringSource33: accessed-variable=prrAlgo34_Flags.u8TriggeringSource
            drparg_u8TriggeringSource34: accessed-variable=prrAlgo35_Flags.u8TriggeringSource
            drparg_u8TriggeringSource35: accessed-variable=prrAlgo36_Flags.u8TriggeringSource
            drparg_u8TriggeringSource36: accessed-variable=prrAlgo37_Flags.u8TriggeringSource
            drparg_u8TriggeringSource37: accessed-variable=prrAlgo38_Flags.u8TriggeringSource
            drparg_u8TriggeringSource4: accessed-variable=prrAlgo05_Flags.u8TriggeringSource
            drparg_u8TriggeringSource5: accessed-variable=prrAlgo06_Flags.u8TriggeringSource
            drparg_u8TriggeringSource6: accessed-variable=prrAlgo07_Flags.u8TriggeringSource
            drparg_u8TriggeringSource7: accessed-variable=prrAlgo08_Flags.u8TriggeringSource
            drparg_u8TriggeringSource8: accessed-variable=prrAlgo09_Flags.u8TriggeringSource
            drparg_u8TriggeringSource9: accessed-variable=prrAlgo10_Flags.u8TriggeringSource
            REC_prrAlgo15_Flags_b8PreActivationFlag: accessed-variable=prrAlgo15_Flags.b8PreActivationFlag
            REC_prrAlgo15_Flags_b8PreConditionsFlag: accessed-variable=prrAlgo15_Flags.b8PreConditionsFlag
        data-send-points:
          access DSP_psrSelect_u8CycleNumber: accessed-variable=psrSelectedCycle.u8CycleNumber  # ARCH_SW_BFS_0091
  swc implementation BFS_AC_BeltFunctionSelection_Implementation: behavior=BFS_IB_BeltFunctionSelection
